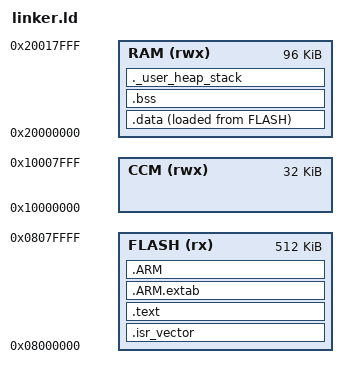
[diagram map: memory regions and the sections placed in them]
/* STM32G474RET6 linker script — 512KB flash, 128KB SRAM + 32KB CCM */
ENTRY(Reset_Handler)

_estack = ORIGIN(RAM) + LENGTH(RAM);
_Min_Heap_Size  = 0x1000;
_Min_Stack_Size = 0x1000;

MEMORY
{
  FLASH (rx) : ORIGIN = 0x08000000, LENGTH = 512K
  RAM   (rwx) : ORIGIN = 0x20000000, LENGTH = 96K
  CCM   (rwx) : ORIGIN = 0x10000000, LENGTH = 32K
}

SECTIONS
{
  .isr_vector :
  {
    . = ALIGN(4);
    KEEP(*(.isr_vector))
    . = ALIGN(4);
  } >FLASH

  .text :
  {
    . = ALIGN(4);
    *(.text)
    *(.text*)
    *(.rodata)
    *(.rodata*)
    . = ALIGN(4);
    _etext = .;
  } >FLASH

  .ARM.extab : { *(.ARM.extab* .gnu.linkonce.armextab.*) } >FLASH
  .ARM : {
    __exidx_start = .;
    *(.ARM.exidx*)
    __exidx_end = .;
  } >FLASH

  _sidata = LOADADDR(.data);
  .data : {
    . = ALIGN(4);
    _sdata = .;
    *(.data)
    *(.data*)
    . = ALIGN(4);
    _edata = .;
  } >RAM AT> FLASH

  .bss : {
    . = ALIGN(4);
    _sbss = .;
    __bss_start__ = .;
    *(.bss)
    *(.bss*)
    *(COMMON)
    . = ALIGN(4);
    _ebss = .;
    __bss_end__ = .;
  } >RAM

  ._user_heap_stack : {
    . = ALIGN(8);
    PROVIDE(end = .);
    PROVIDE(_end = .);
    . = . + _Min_Heap_Size;
    . = . + _Min_Stack_Size;
    . = ALIGN(8);
  } >RAM

  /DISCARD/ : { *(.ARM.attributes) }
}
